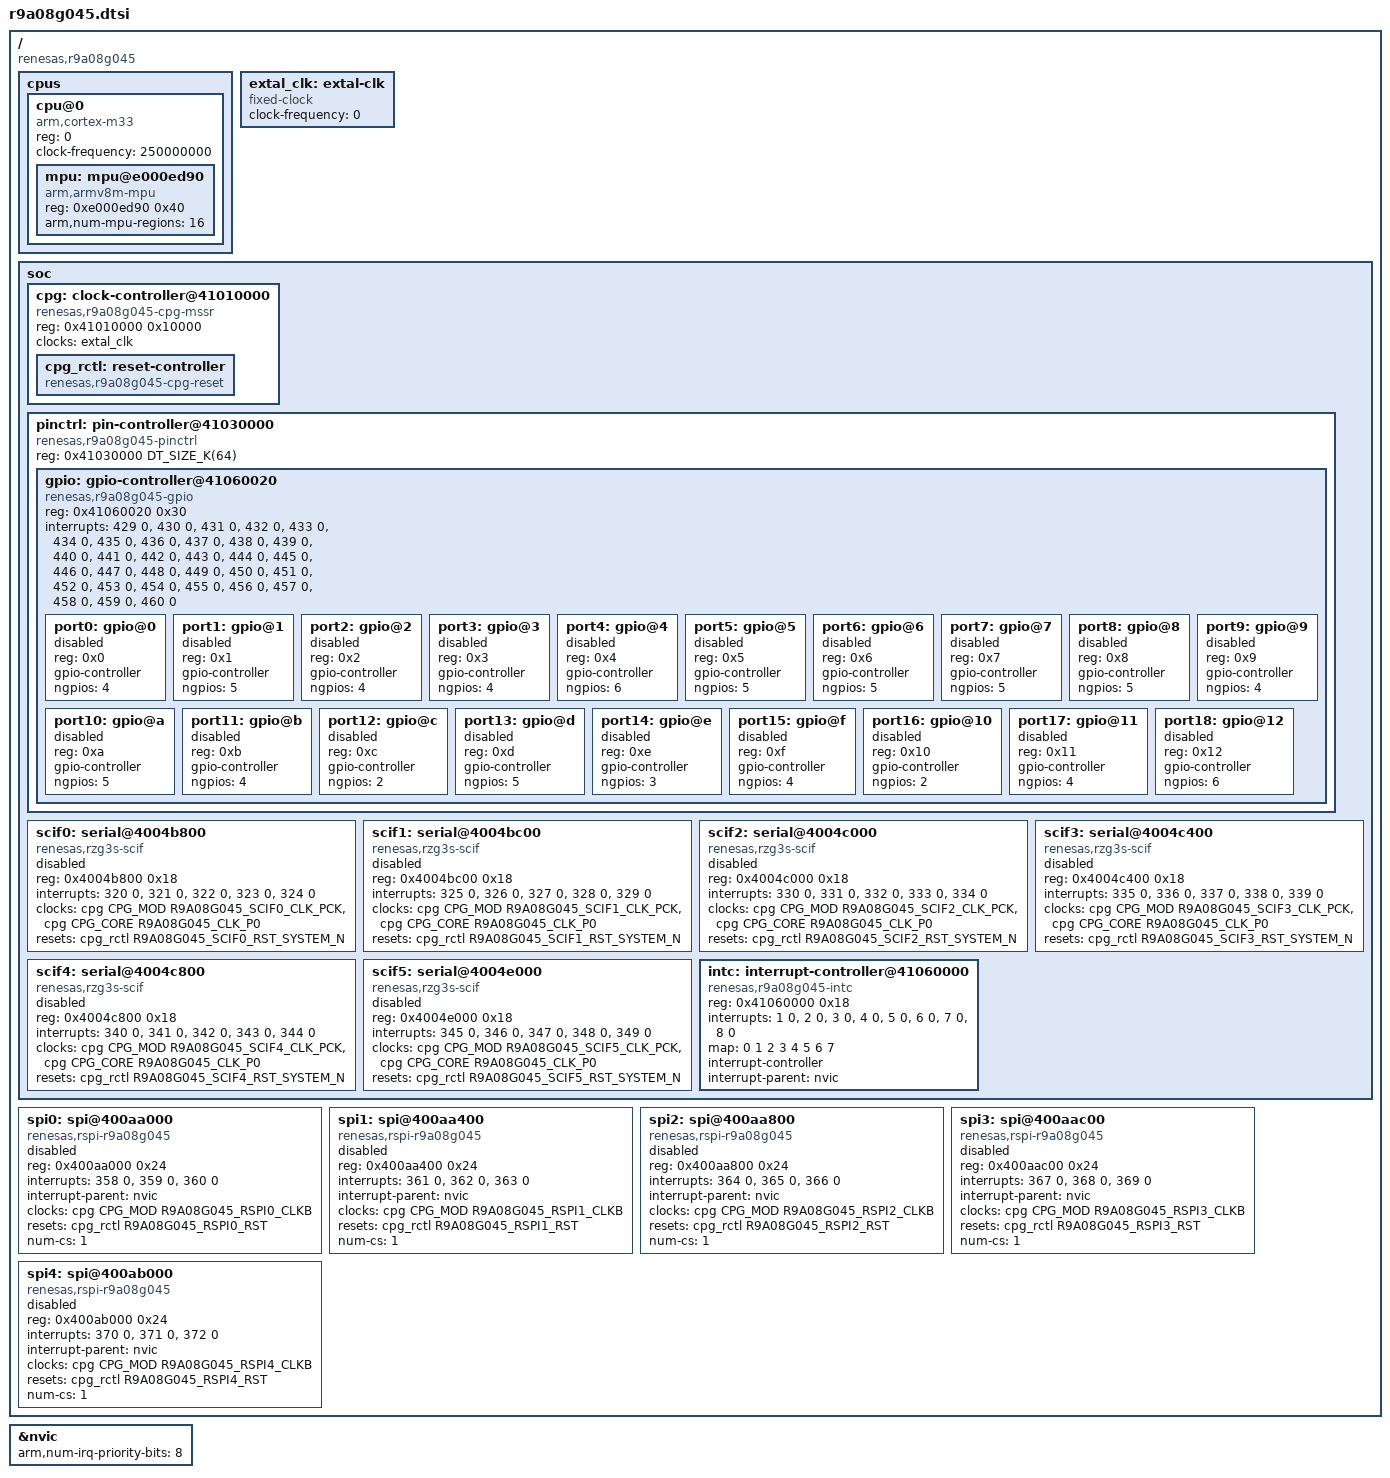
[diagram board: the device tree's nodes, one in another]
/*
 * Copyright (c) 2024 EPAM Systems
 *
 * SPDX-License-Identifier: Apache-2.0
 */

#include <arm/armv8-m.dtsi>
#include <zephyr/dt-bindings/clock/renesas_cpg_mssr.h>
#include <zephyr/dt-bindings/clock/r9a08g045_cpg_mssr.h>
#include <zephyr/dt-bindings/interrupt-controller/r7s9210-intc.h>
#include <zephyr/dt-bindings/dt-util.h>
#include <mem.h>

/ {
	compatible = "renesas,r9a08g045";
	#address-cells = <1>;
	#size-cells = <1>;

	cpus {
		#address-cells = <1>;
		#size-cells = <0>;

		cpu@0 {
			device_type = "cpu";
			compatible = "arm,cortex-m33";
			reg = <0>;
			clock-frequency = <250000000>;
			#address-cells = <1>;
			#size-cells = <1>;

			mpu: mpu@e000ed90 {
				compatible = "arm,armv8m-mpu";
				reg = <0xe000ed90 0x40>;
				arm,num-mpu-regions = <16>;
			};
		};
	};

	extal_clk: extal-clk {
		compatible = "fixed-clock";
		#clock-cells = <0>;
		/* This value must be overridden by the board */
		clock-frequency = <0>;
	};

	soc {
		cpg: clock-controller@41010000 {
			compatible = "renesas,r9a08g045-cpg-mssr";
			reg = <0x41010000 0x10000>;
			clocks = <&extal_clk>;
			clock-names = "extal";
			#clock-cells = <2>;

			cpg_rctl: reset-controller {
				compatible = "renesas,r9a08g045-cpg-reset";
				#reset-cells = <1>;
				status = "okay";
			};
		};

		pinctrl: pin-controller@41030000 {
			compatible = "renesas,r9a08g045-pinctrl";
			reg = <0x41030000 DT_SIZE_K(64)>;
			reg-names = "pinctrl";
			#address-cells = <1>;
			#size-cells = <1>;

			gpio: gpio-controller@41060020 {
				compatible = "renesas,r9a08g045-gpio";
				reg = <0x41060020 0x30>;
				reg-names = "tint";
				interrupts =
					<429 0>, <430 0>, <431 0>, <432 0>,
					<433 0>, <434 0>, <435 0>, <436 0>,
					<437 0>, <438 0>, <439 0>, <440 0>,
					<441 0>, <442 0>, <443 0>, <444 0>,
					<445 0>, <446 0>, <447 0>, <448 0>,
					<449 0>, <450 0>, <451 0>, <452 0>,
					<453 0>, <454 0>, <455 0>, <456 0>,
					<457 0>, <458 0>, <459 0>, <460 0>;
				#address-cells = <1>;
				#size-cells = <0>;

				port0: gpio@0 {
					reg = <0x0>;
					gpio-controller;
					#gpio-cells=<2>;
					ngpios = <4>;
					status = "disabled";
				};

				port1: gpio@1 {
					reg = <0x1>;
					gpio-controller;
					#gpio-cells=<2>;
					ngpios = <5>;
					status = "disabled";
				};

				port2: gpio@2 {
					reg = <0x2>;
					gpio-controller;
					#gpio-cells=<2>;
					ngpios = <4>;
					status = "disabled";
				};

				port3: gpio@3 {
					reg = <0x3>;
					gpio-controller;
					#gpio-cells=<2>;
					ngpios = <4>;
					status = "disabled";
				};

				port4: gpio@4 {
					reg = <0x4>;
					gpio-controller;
					#gpio-cells=<2>;
					ngpios = <6>;
					status = "disabled";
				};

				port5: gpio@5 {
					reg = <0x5>;
					gpio-controller;
					#gpio-cells=<2>;
					ngpios = <5>;
					status = "disabled";
				};

				port6: gpio@6 {
					reg = <0x6>;
					gpio-controller;
					#gpio-cells=<2>;
					ngpios = <5>;
					status = "disabled";
				};

				port7: gpio@7 {
					reg = <0x7>;
					gpio-controller;
					#gpio-cells=<2>;
					ngpios = <5>;
					status = "disabled";
				};

				port8: gpio@8 {
					reg = <0x8>;
					gpio-controller;
					#gpio-cells=<2>;
					ngpios = <5>;
					status = "disabled";
				};

				port9: gpio@9 {
					reg = <0x9>;
					gpio-controller;
					#gpio-cells=<2>;
					ngpios = <4>;
					status = "disabled";
				};

				port10: gpio@a {
					reg = <0xa>;
					gpio-controller;
					#gpio-cells=<2>;
					ngpios = <5>;
					status = "disabled";
				};

				port11: gpio@b {
					reg = <0xb>;
					gpio-controller;
					#gpio-cells=<2>;
					ngpios = <4>;
					status = "disabled";
				};

				port12: gpio@c {
					reg = <0xc>;
					gpio-controller;
					#gpio-cells=<2>;
					ngpios = <2>;
					status = "disabled";
				};

				port13: gpio@d {
					reg = <0xd>;
					gpio-controller;
					#gpio-cells=<2>;
					ngpios = <5>;
					status = "disabled";
				};

				port14: gpio@e {
					reg = <0xe>;
					gpio-controller;
					#gpio-cells=<2>;
					ngpios = <3>;
					status = "disabled";
				};

				port15: gpio@f {
					reg = <0xf>;
					gpio-controller;
					#gpio-cells=<2>;
					ngpios = <4>;
					status = "disabled";
				};

				port16: gpio@10 {
					reg = <0x10>;
					gpio-controller;
					#gpio-cells=<2>;
					ngpios = <2>;
					status = "disabled";
				};

				port17: gpio@11 {
					reg = <0x11>;
					gpio-controller;
					#gpio-cells=<2>;
					ngpios = <4>;
					status = "disabled";
				};

				port18: gpio@12 {
					reg = <0x12>;
					gpio-controller;
					#gpio-cells=<2>;
					ngpios = <6>;
					status = "disabled";
				};
			};
		};

		scif0: serial@4004b800 {
			compatible = "renesas,rzg3s-scif";
			reg = <0x4004b800 0x18>;
			interrupts = <320 0>, <321 0>, <322 0>, <323 0>, <324 0>;
			interrupt-names = "eri", "bri", "rxi", "txi", "tei";
			clocks = <&cpg CPG_MOD R9A08G045_SCIF0_CLK_PCK>,
				 <&cpg CPG_CORE R9A08G045_CLK_P0>;
			clock-names = "fck", "bus";
			resets = <&cpg_rctl R9A08G045_SCIF0_RST_SYSTEM_N>;
			status = "disabled";
		};
		scif1: serial@4004bc00 {
			compatible = "renesas,rzg3s-scif";
			reg = <0x4004bc00 0x18>;
			interrupts = <325 0>, <326 0>, <327 0>, <328 0>, <329 0>;
			interrupt-names = "eri", "bri", "rxi", "txi", "tei";
			clocks = <&cpg CPG_MOD R9A08G045_SCIF1_CLK_PCK>,
				 <&cpg CPG_CORE R9A08G045_CLK_P0>;
			clock-names = "fck", "bus";
			resets = <&cpg_rctl R9A08G045_SCIF1_RST_SYSTEM_N>;
			status = "disabled";
		};
		scif2: serial@4004c000 {
			compatible = "renesas,rzg3s-scif";
			reg = <0x4004c000 0x18>;
			interrupts = <330 0>, <331 0>, <332 0>, <333 0>, <334 0>;
			interrupt-names = "eri", "bri", "rxi", "txi", "tei";
			clocks = <&cpg CPG_MOD R9A08G045_SCIF2_CLK_PCK>,
				 <&cpg CPG_CORE R9A08G045_CLK_P0>;
			clock-names = "fck", "bus";
			resets = <&cpg_rctl R9A08G045_SCIF2_RST_SYSTEM_N>;
			status = "disabled";
		};
		scif3: serial@4004c400 {
			compatible = "renesas,rzg3s-scif";
			reg = <0x4004c400 0x18>;
			interrupts = <335 0>, <336 0>, <337 0>, <338 0>, <339 0>;
			interrupt-names = "eri", "bri", "rxi", "txi", "tei";
			clocks = <&cpg CPG_MOD R9A08G045_SCIF3_CLK_PCK>,
				 <&cpg CPG_CORE R9A08G045_CLK_P0>;
			clock-names = "fck", "bus";
			resets = <&cpg_rctl R9A08G045_SCIF3_RST_SYSTEM_N>;
			status = "disabled";
		};
		scif4: serial@4004c800 {
			compatible = "renesas,rzg3s-scif";
			reg = <0x4004c800 0x18>;
			interrupts = <340 0>, <341 0>, <342 0>, <343 0>, <344 0>;
			interrupt-names = "eri", "bri", "rxi", "txi", "tei";
			clocks = <&cpg CPG_MOD R9A08G045_SCIF4_CLK_PCK>,
				 <&cpg CPG_CORE R9A08G045_CLK_P0>;
			clock-names = "fck", "bus";
			resets = <&cpg_rctl R9A08G045_SCIF4_RST_SYSTEM_N>;
			status = "disabled";
		};
		scif5: serial@4004e000 {
			compatible = "renesas,rzg3s-scif";
			reg = <0x4004e000 0x18>;
			interrupts = <345 0>, <346 0>, <347 0>, <348 0>, <349 0>;
			interrupt-names = "eri", "bri", "rxi", "txi", "tei";
			clocks = <&cpg CPG_MOD R9A08G045_SCIF5_CLK_PCK>,
				 <&cpg CPG_CORE R9A08G045_CLK_P0>;
			clock-names = "fck", "bus";
			resets = <&cpg_rctl R9A08G045_SCIF5_RST_SYSTEM_N>;
			status = "disabled";
		};

		intc: interrupt-controller@41060000 {
			compatible = "renesas,r9a08g045-intc";
			reg = <0x41060000 0x18>;
			#interrupt-cells = <2>;
			#address-cells = <0>;
			interrupts =
				<1 0>, <2 0>, <3 0>, <4 0>,
				<5 0>, <6 0>, <7 0>, <8 0>;
			map = <0 1 2 3 4 5 6 7>;
			interrupt-controller;
			interrupt-parent = <&nvic>;
		};
	};

	spi0: spi@400aa000 {
		compatible = "renesas,rspi-r9a08g045", "renesas,rspi-rz";
		reg = <0x400aa000 0x24>;
		interrupts = <358 0>, <359 0>, <360 0>;
		interrupt-names = "error", "rx", "tx";
		interrupt-parent = <&nvic>;
		clocks = <&cpg CPG_MOD R9A08G045_RSPI0_CLKB>;
		resets = <&cpg_rctl R9A08G045_RSPI0_RST>;
		num-cs = <1>;
		#address-cells = <1>;
		#size-cells = <0>;
		status = "disabled";
	};

	spi1: spi@400aa400 {
		compatible = "renesas,rspi-r9a08g045", "renesas,rspi-rz";
		reg = <0x400aa400 0x24>;
		interrupts = <361 0>, <362 0>, <363 0>;
		interrupt-names = "error", "rx", "tx";
		interrupt-parent = <&nvic>;
		clocks = <&cpg CPG_MOD R9A08G045_RSPI1_CLKB>;
		resets = <&cpg_rctl R9A08G045_RSPI1_RST>;
		num-cs = <1>;
		#address-cells = <1>;
		#size-cells = <0>;
		status = "disabled";
	};

	spi2: spi@400aa800 {
		compatible = "renesas,rspi-r9a08g045", "renesas,rspi-rz";
		reg = <0x400aa800 0x24>;
		interrupts = <364 0>, <365 0>, <366 0>;
		interrupt-names = "error", "rx", "tx";
		interrupt-parent = <&nvic>;
		clocks = <&cpg CPG_MOD R9A08G045_RSPI2_CLKB>;
		resets = <&cpg_rctl R9A08G045_RSPI2_RST>;
		num-cs = <1>;
		#address-cells = <1>;
		#size-cells = <0>;
		status = "disabled";
	};

	spi3: spi@400aac00 {
		compatible = "renesas,rspi-r9a08g045", "renesas,rspi-rz";
		reg = <0x400aac00 0x24>;
		interrupts = <367 0>, <368 0>, <369 0>;
		interrupt-names = "error", "rx", "tx";
		interrupt-parent = <&nvic>;
		clocks = <&cpg CPG_MOD R9A08G045_RSPI3_CLKB>;
		resets = <&cpg_rctl R9A08G045_RSPI3_RST>;
		num-cs = <1>;
		#address-cells = <1>;
		#size-cells = <0>;
		status = "disabled";
	};

	spi4: spi@400ab000 {
		compatible = "renesas,rspi-r9a08g045", "renesas,rspi-rz";
		reg = <0x400ab000 0x24>;
		interrupts = <370 0>, <371 0>, <372 0>;
		interrupt-names = "error", "rx", "tx";
		interrupt-parent = <&nvic>;
		clocks = <&cpg CPG_MOD R9A08G045_RSPI4_CLKB>;
		resets = <&cpg_rctl R9A08G045_RSPI4_RST>;
		num-cs = <1>;
		#address-cells = <1>;
		#size-cells = <0>;
		status = "disabled";
	};
};

&nvic {
	arm,num-irq-priority-bits = <8>;
};
